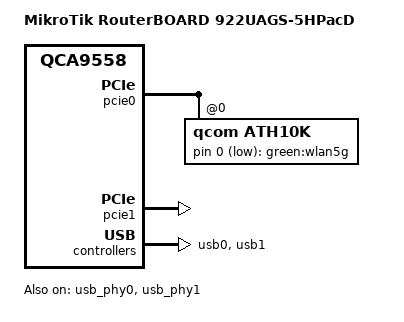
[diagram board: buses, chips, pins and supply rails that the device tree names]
// SPDX-License-Identifier: GPL-2.0-or-later OR MIT

#include "qca9558_mikrotik_routerboard-92x.dtsi"

/ {
	compatible = "mikrotik,routerboard-922uags-5hpacd", "qca,qca9558";
	model = "MikroTik RouterBOARD 922UAGS-5HPacD";

	ath10k-leds {
		compatible = "gpio-leds";

		wlan5g {
			label = "green:wlan5g";
			gpios = <&ath10k 0 GPIO_ACTIVE_LOW>;
			linux,default-trigger = "phy0tpt";
		};
	};

	gpio-export {
		gpio_usb_power {
			gpio-export,name = "mikrotik:power:usb";
			gpio-export,output = <0>;
			gpios = <&gpio 13 GPIO_ACTIVE_HIGH>;
		};
	};
};

&pcie0 {
	status = "okay";

	ath10k: wifi@0,0 {
		compatible = "qcom,ath10k";
		reg = <0 0 0 0 0>;
		#gpio-cells = <2>;
		gpio-controller;
	};
};

&pcie1 {
	status = "okay";
};

&usb0 {
	status = "okay";
};

&usb_phy0 {
	status = "okay";
};

&usb1 {
	status = "okay";
};

&usb_phy1 {
	status = "okay";
};
